VERSION ""

NS_ :

BS_:

BU_: ControlECU STM32Tool

VAL_TABLE_ vt_GearPosition 3 "D" 2 "N" 1 "R" 0 "P" ;
VAL_TABLE_ vt_HighLowBeam 2 "High_Beam" 1 "Low_Beam" 0 "OFF" ;
VAL_TABLE_ vt_TurnSignal 3 "HAZARD" 2 "RIGHT" 1 "LEFT" 0 "OFF" ;
VAL_TABLE_ vt_FlashLight 1 "Flash" 0 "Normal" ;
VAL_TABLE_ vt_WiperSpeed 4 "HIGH" 3 "LOW" 2 "INT2" 1 "INT1" 0 "OFF" ;
VAL_TABLE_ vt_WiperWasher 1 "ACTIVE" 0 "OFF" ;
VAL_TABLE_ vt_HeadlightMode 3 "FOLD" 2 "FOG" 1 "AUTO" 0 "OFF" ;

BO_ 801 SS_Right_CMD: 1 ControlECU
 SG_ Gear_Cmd : 0|3@1+ (1,0) [0|3] "State"  STM32Tool

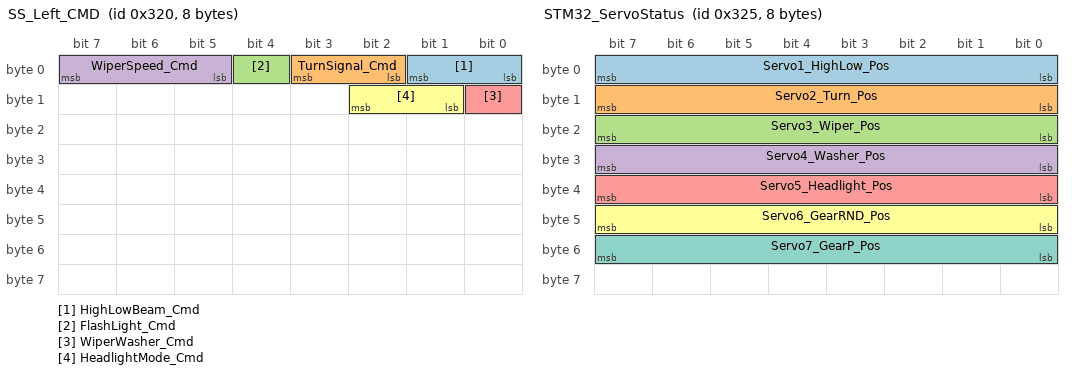
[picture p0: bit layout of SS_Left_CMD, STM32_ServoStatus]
BO_ 800 SS_Left_CMD: 8 ControlECU
 SG_ HighLowBeam_Cmd : 0|2@1+ (1,0) [0|2] ""  STM32Tool
 SG_ TurnSignal_Cmd : 2|2@1+ (1,0) [0|3] ""  STM32Tool
 SG_ FlashLight_Cmd : 4|1@1+ (1,0) [0|1] ""  STM32Tool
 SG_ WiperSpeed_Cmd : 5|3@1+ (1,0) [0|4] ""  STM32Tool
 SG_ WiperWasher_Cmd : 8|1@1+ (1,0) [0|1] ""  STM32Tool
 SG_ HeadlightMode_Cmd : 9|2@1+ (1,0) [0|3] ""  STM32Tool

BO_ 805 STM32_ServoStatus: 8 STM32Tool
 SG_ Servo1_HighLow_Pos : 0|8@1+ (1,0) [0|180] "deg"  ControlECU
 SG_ Servo2_Turn_Pos : 8|8@1+ (1,0) [0|180] "deg"  ControlECU
 SG_ Servo3_Wiper_Pos : 16|8@1+ (1,0) [0|180] "deg"  ControlECU
 SG_ Servo4_Washer_Pos : 24|8@1+ (1,0) [0|180] "deg"  ControlECU
 SG_ Servo5_Headlight_Pos : 32|8@1+ (1,0) [0|180] "deg"  ControlECU
 SG_ Servo6_GearRND_Pos : 40|8@1+ (1,0) [0|180] "deg"  ControlECU
 SG_ Servo7_GearP_Pos : 48|8@1+ (1,0) [0|180] "deg"  ControlECU

CM_ BU_ ControlECU "Master ECU responsible for transmitting vehicle body control commands to the STM32Tool slave node.";
CM_ BU_ STM32Tool "Slave node controlling 7 servo motors and reporting servo position feedback to ControlECU.";
CM_ BO_ 800 "BCM_LightRainCmd: Body Control Module command message transmitted by ControlECU at 50 ms cycle.";
CM_ SG_ 801 Gear_Cmd "Gear command";
CM_ SG_ 800 HighLowBeam_Cmd "Headlight beam selection command. 0=OFF, 1=Low Beam, 2=High Beam.";
CM_ SG_ 800 TurnSignal_Cmd "Turn signal indicator command. 0=OFF, 1=LEFT, 2=RIGHT, 3=HAZARD.";
CM_ SG_ 800 FlashLight_Cmd "Headlight flash command. 0=Normal, 1=Flash active.";
CM_ SG_ 800 WiperSpeed_Cmd "Front wiper speed command. 0=OFF, 1=INT1, 2=INT2, 3=LOW, 4=HIGH.";
CM_ SG_ 800 WiperWasher_Cmd "Windshield washer pump command. 0=OFF, 1=ACTIVE.";
CM_ SG_ 800 HeadlightMode_Cmd "Headlight mode command. 0=OFF, 1=AUTO, 2=FOG, 3=FOLD.";
CM_ BO_ 805 "STM32_ServoStatus: Servo motor position feedback message transmitted by STM32Tool at 100 ms cycle.";
CM_ SG_ 805 Servo1_HighLow_Pos "Servo 1 angular position for high/low beam actuator. Range 0-180 deg.";
CM_ SG_ 805 Servo2_Turn_Pos "Servo 2 angular position for turn signal actuator. Range 0-180 deg.";
CM_ SG_ 805 Servo3_Wiper_Pos "Servo 3 angular position for wiper actuator. Range 0-180 deg.";
CM_ SG_ 805 Servo4_Washer_Pos "Servo 4 angular position for washer actuator. Range 0-180 deg.";
CM_ SG_ 805 Servo5_Headlight_Pos "Servo 5 angular position for headlight mode actuator. Range 0-180 deg.";
CM_ SG_ 805 Servo6_GearRND_Pos "Servo 6 angular position representing actual Gear R/N/D position. Range 0-180 deg.";
CM_ SG_ 805 Servo7_GearP_Pos "Servo 7 angular position representing actual Gear P (Park Lock) position. Range 0-180 deg.";

BA_DEF_ BO_  "GenMsgCycleTime" INT 0 10000;
BA_DEF_ BO_  "GenMsgSendType" STRING ;
BA_DEF_ BO_  "GenMsgStartDelayTime" INT 0 10000;
BA_DEF_ SG_  "GenSigStartValue" INT 0 65535;
BA_DEF_ SG_  "GenSigSendType" STRING ;

BA_DEF_DEF_  "GenMsgCycleTime" 0;
BA_DEF_DEF_  "GenMsgSendType" "Cyclic";
BA_DEF_DEF_  "GenMsgStartDelayTime" 0;
BA_DEF_DEF_  "GenSigStartValue" 0;
BA_DEF_DEF_  "GenSigSendType" "Cyclic";

BA_ "GenMsgCycleTime" BO_ 801 50;
BA_ "GenMsgCycleTime" BO_ 800 50;
BA_ "GenMsgCycleTime" BO_ 805 100;

VAL_ 801 Gear_Cmd 3 "D" 2 "N" 1 "R" 0 "P" ;
VAL_ 800 HighLowBeam_Cmd 2 "High_Beam" 1 "Low_Beam" 0 "OFF" ;
VAL_ 800 TurnSignal_Cmd 3 "HAZARD" 2 "RIGHT" 1 "LEFT" 0 "OFF" ;
VAL_ 800 FlashLight_Cmd 1 "Flash" 0 "Normal" ;
VAL_ 800 WiperSpeed_Cmd 4 "HIGH" 3 "LOW" 2 "INT2" 1 "INT1" 0 "OFF" ;
VAL_ 800 WiperWasher_Cmd 1 "ACTIVE" 0 "OFF" ;
VAL_ 800 HeadlightMode_Cmd 3 "FOLD" 2 "FOG" 1 "AUTO" 0 "OFF" ;
